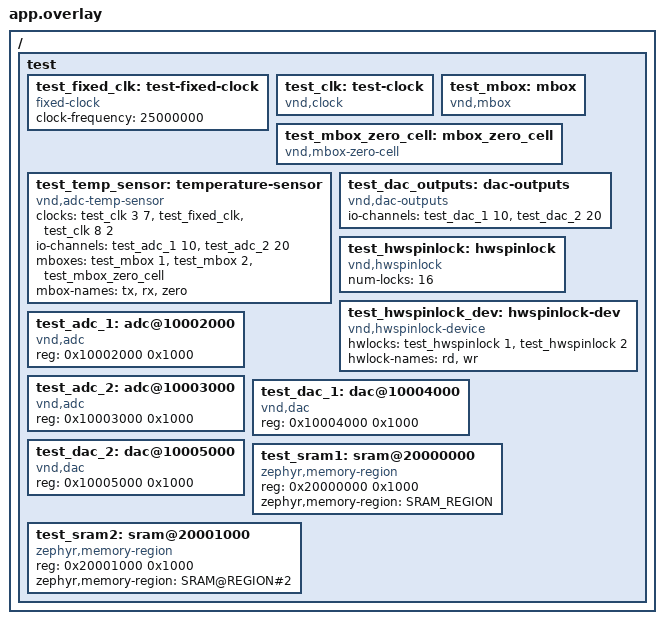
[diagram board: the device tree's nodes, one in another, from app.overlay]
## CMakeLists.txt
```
# SPDX-License-Identifier: Apache-2.0

cmake_minimum_required(VERSION 3.28.0)

find_package(Zephyr REQUIRED HINTS $ENV{ZEPHYR_BASE})
project(devicetree_extensions)

FILE(GLOB app_sources src/*.c)
target_sources(app PRIVATE ${app_sources})
```

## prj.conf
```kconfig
CONFIG_ZTEST=y
CONFIG_ADC=y
CONFIG_DAC=y
CONFIG_MBOX=y
CONFIG_HWSPINLOCK=y
CONFIG_SPIN_VALIDATE=n
```

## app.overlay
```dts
/*
 * Copyright (c) 2021, Commonwealth Scientific and Industrial Research
 * Organisation (CSIRO) ABN 41 687 119 230.
 * Copyright (c) 2025 Analog Devices, Inc.
 *
 * SPDX-License-Identifier: Apache-2.0
 *
 * Application overlay for testing the devicetree.h extension API's.
 *
 * Names in this file should be chosen in a way that won't conflict
 * with real-world devicetree nodes, to allow these tests to run on
 * (and be extended to test) real hardware.
 */

/ {
	test {
		#address-cells = <0x1>;
		#size-cells = <0x1>;

		test_fixed_clk: test-fixed-clock {
			compatible = "fixed-clock";
			clock-frequency = <25000000>;
			#clock-cells = <0>;
		};

		test_clk: test-clock {
			compatible = "vnd,clock";
			#clock-cells = <2>;
		};

		test_mbox: mbox {
			compatible = "vnd,mbox";
			#mbox-cells = <1>;
			status = "okay";
		};

		test_mbox_zero_cell: mbox_zero_cell {
			compatible = "vnd,mbox-zero-cell";
			#mbox-cells = <0>;
			status = "okay";
		};

		/* there should only be one of these */
		test_temp_sensor: temperature-sensor {
			compatible = "vnd,adc-temp-sensor";
			clocks = <&test_clk 3 7>, <&test_fixed_clk>, <&test_clk 8 2>;
			clock-names = "clk-a", "clk-fixed", "clk-b";
			io-channels = <&test_adc_1 10>, <&test_adc_2 20>;
			io-channel-names = "ch1", "ch2";
			mboxes = <&test_mbox 1>, <&test_mbox 2>, <&test_mbox_zero_cell>;
			mbox-names = "tx", "rx", "zero";
		};

		/* there should only be one of these */
		test_dac_outputs: dac-outputs {
			compatible = "vnd,dac-outputs";
			io-channels = <&test_dac_1 10>, <&test_dac_2 20>;
			io-channel-names = "ch1", "ch2";
		};

		test_hwspinlock: hwspinlock {
			compatible = "vnd,hwspinlock";
			#hwlock-cells = <1>;
			num-locks = <16>;
			status = "okay";
		};

		test_hwspinlock_dev: hwspinlock-dev {
			compatible = "vnd,hwspinlock-device";
			hwlocks = <&test_hwspinlock 1>, <&test_hwspinlock 2>;
			hwlock-names = "rd", "wr";
			status = "okay";
		};

		test_adc_1: adc@10002000 {
			compatible = "vnd,adc";
			reg = <0x10002000 0x1000>;
			#io-channel-cells = <1>;
			status = "okay";
		};

		test_adc_2: adc@10003000 {
			compatible = "vnd,adc";
			reg = <0x10003000 0x1000>;
			#io-channel-cells = <1>;
			status = "okay";
		};

		test_dac_1: dac@10004000 {
			compatible = "vnd,dac";
			reg = <0x10004000 0x1000>;
			#io-channel-cells = <1>;
			status = "okay";
		};

		test_dac_2: dac@10005000 {
			compatible = "vnd,dac";
			reg = <0x10005000 0x1000>;
			#io-channel-cells = <1>;
			status = "okay";
		};

		test_sram1: sram@20000000 {
			compatible = "zephyr,memory-region", "mmio-sram";
			reg = <0x20000000 0x1000>;
			zephyr,memory-region = "SRAM_REGION";
		};

		test_sram2: sram@20001000 {
			compatible = "zephyr,memory-region", "mmio-sram";
			reg = <0x20001000 0x1000>;
			zephyr,memory-region = "SRAM@REGION#2";
		};
	};
};
```

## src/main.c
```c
/*
 * Copyright (c) 2021, Commonwealth Scientific and Industrial Research
 * Organisation (CSIRO) ABN 41 687 119 230.
 * Copyright (c) 2025 Analog Devices, Inc.
 *
 * SPDX-License-Identifier: Apache-2.0
 */

#include <zephyr/ztest.h>
#include <zephyr/devicetree.h>
#include <zephyr/device.h>
#include <zephyr/drivers/gpio.h>
#include <zephyr/drivers/adc.h>
#include <zephyr/drivers/dac.h>
#include <zephyr/drivers/mbox.h>
#include <zephyr/drivers/hwspinlock.h>

#include <zephyr/linker/devicetree_regions.h>

#define TEST_SRAM1 DT_NODELABEL(test_sram1)
#define TEST_SRAM2 DT_NODELABEL(test_sram2)
#define TEST_TEMP  DT_NODELABEL(test_temp_sensor)
#define TEST_DAC   DT_NODELABEL(test_dac_outputs)
#define TEST_MISSING DT_NODELABEL(test_non_existing)

ZTEST(devicetree_api_ext, test_linker_regions)
{
	zassert_true(!strcmp(LINKER_DT_NODE_REGION_NAME(TEST_SRAM1), "SRAM_REGION"), "");
	zassert_true(!strcmp(LINKER_DT_NODE_REGION_NAME(TEST_SRAM2), "SRAM_REGION_2"), "");
}

#define DT_DRV_COMPAT vnd_adc_temp_sensor
ZTEST(devicetree_api_ext, test_adc_dt_spec)
{
	struct adc_dt_spec adc_spec;

	/* ADC_DT_SPEC_GET_BY_NAME */
	adc_spec = (struct adc_dt_spec)ADC_DT_SPEC_GET_BY_NAME(TEST_TEMP, ch1);
	zexpect_equal(adc_spec.channel_id, 10, "");

	adc_spec = (struct adc_dt_spec)ADC_DT_SPEC_GET_BY_NAME(TEST_TEMP, ch2);
	zexpect_equal(adc_spec.channel_id, 20, "");

	/* ADC_DT_SPEC_INST_GET_BY_NAME */
	adc_spec = (struct adc_dt_spec)ADC_DT_SPEC_INST_GET_BY_NAME(0, ch1);
	zexpect_equal(adc_spec.channel_id, 10, "");

	adc_spec = (struct adc_dt_spec)ADC_DT_SPEC_INST_GET_BY_NAME(0, ch2);
	zexpect_equal(adc_spec.channel_id, 20, "");

	/* ADC_DT_SPEC_GET_BY_IDX */
	adc_spec = (struct adc_dt_spec)ADC_DT_SPEC_GET_BY_IDX(TEST_TEMP, 0);
	zexpect_equal(adc_spec.channel_id, 10, "");

	adc_spec = (struct adc_dt_spec)ADC_DT_SPEC_GET_BY_IDX(TEST_TEMP, 1);
	zexpect_equal(adc_spec.channel_id, 20, "");

	/* ADC_DT_SPEC_INST_GET_BY_IDX */
	adc_spec = (struct adc_dt_spec)ADC_DT_SPEC_INST_GET_BY_IDX(0, 0);
	zexpect_equal(adc_spec.channel_id, 10, "");

	adc_spec = (struct adc_dt_spec)ADC_DT_SPEC_INST_GET_BY_IDX(0, 1);
	zexpect_equal(adc_spec.channel_id, 20, "");

	/* ADC_DT_SPEC_GET_BY_NAME_OR */
	adc_spec = (struct adc_dt_spec)ADC_DT_SPEC_GET_BY_NAME_OR(TEST_TEMP, ch1, {0});
	zexpect_equal(adc_spec.channel_id, 10, "");

	adc_spec = (struct adc_dt_spec)ADC_DT_SPEC_GET_BY_NAME_OR(TEST_TEMP, ch2, {0});
	zexpect_equal(adc_spec.channel_id, 20, "");

	adc_spec = (struct adc_dt_spec)ADC_DT_SPEC_GET_BY_NAME_OR(TEST_TEMP, ch_missing, {0});
	zexpect_equal(adc_spec.channel_id, 0, "");

	adc_spec = (struct adc_dt_spec)ADC_DT_SPEC_GET_BY_NAME_OR(TEST_MISSING, ch1, {0});
	zexpect_equal(adc_spec.channel_id, 0, "");

	/* ADC_DT_SPEC_INST_GET_BY_NAME_OR */
	adc_spec = (struct adc_dt_spec)ADC_DT_SPEC_INST_GET_BY_NAME_OR(0, ch1, {0});
	zexpect_equal(adc_spec.channel_id, 10, "");

	adc_spec = (struct adc_dt_spec)ADC_DT_SPEC_INST_GET_BY_NAME_OR(0, ch2, {0});
	zexpect_equal(adc_spec.channel_id, 20, "");

	adc_spec = (struct adc_dt_spec)ADC_DT_SPEC_INST_GET_BY_NAME_OR(0, ch_missing, {0});
	zexpect_equal(adc_spec.channel_id, 0, "");

	adc_spec = (struct adc_dt_spec)ADC_DT_SPEC_INST_GET_BY_NAME_OR(100, ch1, {0});
	zexpect_equal(adc_spec.channel_id, 0, "");

	/* ADC_DT_SPEC_GET_BY_IDX_OR */
	adc_spec = (struct adc_dt_spec)ADC_DT_SPEC_GET_BY_IDX_OR(TEST_TEMP, 0, {0});
	zexpect_equal(adc_spec.channel_id, 10, "");

	adc_spec = (struct adc_dt_spec)ADC_DT_SPEC_GET_BY_IDX_OR(TEST_TEMP, 1, {0});
	zexpect_equal(adc_spec.channel_id, 20, "");

	adc_spec = (struct adc_dt_spec)ADC_DT_SPEC_GET_BY_IDX_OR(TEST_TEMP, 100, {0});
	zexpect_equal(adc_spec.channel_id, 0, "");

	adc_spec = (struct adc_dt_spec)ADC_DT_SPEC_GET_BY_IDX_OR(TEST_MISSING, 0, {0});
	zexpect_equal(adc_spec.channel_id, 0, "");

	/* ADC_DT_SPEC_INST_GET_BY_IDX_OR */
	adc_spec = (struct adc_dt_spec)ADC_DT_SPEC_INST_GET_BY_IDX_OR(0, 0, {0});
	zexpect_equal(adc_spec.channel_id, 10, "");

	adc_spec = (struct adc_dt_spec)ADC_DT_SPEC_INST_GET_BY_IDX_OR(0, 1, {0});
	zexpect_equal(adc_spec.channel_id, 20, "");

	adc_spec = (struct adc_dt_spec)ADC_DT_SPEC_INST_GET_BY_IDX_OR(0, 100, {0});
	zexpect_equal(adc_spec.channel_id, 0, "");

	adc_spec = (struct adc_dt_spec)ADC_DT_SPEC_INST_GET_BY_IDX_OR(100, 0, {0});
	zexpect_equal(adc_spec.channel_id, 0, "");
}

#undef DT_DRV_COMPAT
#define DT_DRV_COMPAT vnd_dac_outputs
ZTEST(devicetree_api_ext, test_dac_dt_spec)
{
	struct dac_dt_spec dac_spec;

	/* DAC_DT_SPEC_GET_BY_NAME */
	dac_spec = (struct dac_dt_spec)DAC_DT_SPEC_GET_BY_NAME(TEST_DAC, ch1);
	zexpect_equal(dac_spec.channel_id, 10, "");

	dac_spec = (struct dac_dt_spec)DAC_DT_SPEC_GET_BY_NAME(TEST_DAC, ch2);
	zexpect_equal(dac_spec.channel_id, 20, "");

	/* DAC_DT_SPEC_INST_GET_BY_NAME */
	dac_spec = (struct dac_dt_spec)DAC_DT_SPEC_INST_GET_BY_NAME(0, ch1);
	zexpect_equal(dac_spec.channel_id, 10, "");

	dac_spec = (struct dac_dt_spec)DAC_DT_SPEC_INST_GET_BY_NAME(0, ch2);
	zexpect_equal(dac_spec.channel_id, 20, "");

	/* DAC_DT_SPEC_GET_BY_IDX */
	dac_spec = (struct dac_dt_spec)DAC_DT_SPEC_GET_BY_IDX(TEST_DAC, 0);
	zexpect_equal(dac_spec.channel_id, 10, "");

	dac_spec = (struct dac_dt_spec)DAC_DT_SPEC_GET_BY_IDX(TEST_DAC, 1);
	zexpect_equal(dac_spec.channel_id, 20, "");

	/* DAC_DT_SPEC_INST_GET_BY_IDX */
	dac_spec = (struct dac_dt_spec)DAC_DT_SPEC_INST_GET_BY_IDX(0, 0);
	zexpect_equal(dac_spec.channel_id, 10, "");

	dac_spec = (struct dac_dt_spec)DAC_DT_SPEC_INST_GET_BY_IDX(0, 1);
	zexpect_equal(dac_spec.channel_id, 20, "");

	/* DAC_DT_SPEC_GET_BY_NAME_OR */
	dac_spec = (struct dac_dt_spec)DAC_DT_SPEC_GET_BY_NAME_OR(TEST_DAC, ch1, {0});
	zexpect_equal(dac_spec.channel_id, 10, "");

	dac_spec = (struct dac_dt_spec)DAC_DT_SPEC_GET_BY_NAME_OR(TEST_DAC, ch2, {0});
	zexpect_equal(dac_spec.channel_id, 20, "");

	dac_spec = (struct dac_dt_spec)DAC_DT_SPEC_GET_BY_NAME_OR(TEST_DAC, ch_missing, {0});
	zexpect_equal(dac_spec.channel_id, 0, "");

	dac_spec = (struct dac_dt_spec)DAC_DT_SPEC_GET_BY_NAME_OR(TEST_MISSING, ch1, {0});
	zexpect_equal(dac_spec.channel_id, 0, "");

	/* DAC_DT_SPEC_INST_GET_BY_NAME_OR */
	dac_spec = (struct dac_dt_spec)DAC_DT_SPEC_INST_GET_BY_NAME_OR(0, ch1, {0});
	zexpect_equal(dac_spec.channel_id, 10, "");

	dac_spec = (struct dac_dt_spec)DAC_DT_SPEC_INST_GET_BY_NAME_OR(0, ch2, {0});
	zexpect_equal(dac_spec.channel_id, 20, "");

	dac_spec = (struct dac_dt_spec)DAC_DT_SPEC_INST_GET_BY_NAME_OR(0, ch_missing, {0});
	zexpect_equal(dac_spec.channel_id, 0, "");

	dac_spec = (struct dac_dt_spec)DAC_DT_SPEC_INST_GET_BY_NAME_OR(100, ch1, {0});
	zexpect_equal(dac_spec.channel_id, 0, "");

	/* DAC_DT_SPEC_GET_BY_IDX_OR */
	dac_spec = (struct dac_dt_spec)DAC_DT_SPEC_GET_BY_IDX_OR(TEST_DAC, 0, {0});
	zexpect_equal(dac_spec.channel_id, 10, "");

	dac_spec = (struct dac_dt_spec)DAC_DT_SPEC_GET_BY_IDX_OR(TEST_DAC, 1, {0});
	zexpect_equal(dac_spec.channel_id, 20, "");

	dac_spec = (struct dac_dt_spec)DAC_DT_SPEC_GET_BY_IDX_OR(TEST_DAC, 100, {0});
	zexpect_equal(dac_spec.channel_id, 0, "");

	dac_spec = (struct dac_dt_spec)DAC_DT_SPEC_GET_BY_IDX_OR(TEST_MISSING, 0, {0});
	zexpect_equal(dac_spec.channel_id, 0, "");

	/* DAC_DT_SPEC_INST_GET_BY_IDX_OR */
	dac_spec = (struct dac_dt_spec)DAC_DT_SPEC_INST_GET_BY_IDX_OR(0, 0, {0});
	zexpect_equal(dac_spec.channel_id, 10, "");

	dac_spec = (struct dac_dt_spec)DAC_DT_SPEC_INST_GET_BY_IDX_OR(0, 1, {0});
	zexpect_equal(dac_spec.channel_id, 20, "");

	dac_spec = (struct dac_dt_spec)DAC_DT_SPEC_INST_GET_BY_IDX_OR(0, 100, {0});
	zexpect_equal(dac_spec.channel_id, 0, "");

	dac_spec = (struct dac_dt_spec)DAC_DT_SPEC_INST_GET_BY_IDX_OR(100, 0, {0});
	zexpect_equal(dac_spec.channel_id, 0, "");
}

DEVICE_DT_DEFINE(DT_NODELABEL(test_mbox), NULL, NULL, NULL, NULL, POST_KERNEL, 90, NULL);
DEVICE_DT_DEFINE(DT_NODELABEL(test_mbox_zero_cell), NULL, NULL, NULL, NULL, POST_KERNEL, 90, NULL);
ZTEST(devicetree_api_ext, test_mbox_dt_spec)
{
	const struct mbox_dt_spec channel_tx = MBOX_DT_SPEC_GET(TEST_TEMP, tx);
	const struct mbox_dt_spec channel_rx = MBOX_DT_SPEC_GET(TEST_TEMP, rx);

	zassert_equal(channel_tx.channel_id, 1, "");
	zassert_equal(channel_rx.channel_id, 2, "");

	const struct mbox_dt_spec channel_zero = MBOX_DT_SPEC_GET(TEST_TEMP, zero);

	zassert_equal(channel_zero.channel_id, 0, "");
}

#define TEST_HWSPINLOCK \
	DT_NODELABEL(test_hwspinlock)

#define TEST_HWSPINLOCK_DEV \
	DT_NODELABEL(test_hwspinlock_dev)

#define HWSPINLOCK_BY_IDX(node_id, prop, idx) \
	HWSPINLOCK_DT_SPEC_GET_BY_IDX(node_id, idx)

static const struct hwspinlock_dt_spec spec[] = {
	DT_FOREACH_PROP_ELEM_SEP(TEST_HWSPINLOCK_DEV, hwlocks, HWSPINLOCK_BY_IDX, (,))
};

static const struct hwspinlock_dt_spec rd =
	HWSPINLOCK_DT_SPEC_GET_BY_NAME(TEST_HWSPINLOCK_DEV, rd);

static const struct hwspinlock_dt_spec wr =
	HWSPINLOCK_DT_SPEC_GET_BY_NAME(TEST_HWSPINLOCK_DEV, wr);

ZTEST(devicetree_api_ext, test_hwspinlock_dt_spec)
{
	for (int i = 0; i < ARRAY_SIZE(spec); i++) {
		zassert_equal(spec[i].dev, DEVICE_DT_GET(TEST_HWSPINLOCK));
		zassert_equal(spec[i].id, i + 1);
	}

	zassert_equal(rd.dev, DEVICE_DT_GET(TEST_HWSPINLOCK));
	zassert_equal(rd.id, 1);

	zassert_equal(wr.dev, DEVICE_DT_GET(TEST_HWSPINLOCK));
	zassert_equal(wr.id, 2);
}

ZTEST_SUITE(devicetree_api_ext, NULL, NULL, NULL, NULL, NULL);
```
